AUTOSAR XML (schema 00049)
package /RB/PT/PCT_DcmSample_Requester/SwComponentTypes
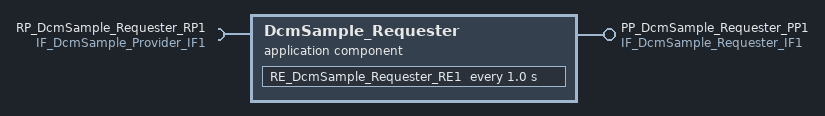
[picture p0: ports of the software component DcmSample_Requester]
  application sw component type DcmSample_Requester
    provide port PP_DcmSample_Requester_PP1: provided-interface=IF_DcmSample_Requester_IF1
    require port RP_DcmSample_Requester_RP1: required-interface=IF_DcmSample_Provider_IF1
    behavior IB_DcmSample_Requester_IB1: data-type-mapping=DTMS_DcmSample_Requester
      timing event TE_DcmSample_Requester_TE1: start-on-event=RE_DcmSample_Requester_RE1, period=1.0
      runnable RE_DcmSample_Requester_RE1: symbol=DcmSample_Requester_1000ms
        data-receive-point-by-values:
          access DRP_DcmSample_Requester_DRP1: accessed-variable=RP_DcmSample_Requester_RP1.VDP_DcmSample_Provider_Var1
        data-send-points:
          access DSP_DcmSample_Requester_DSP1: accessed-variable=PP_DcmSample_Requester_PP1.VDP_DcmSample_Requester_Var1
package /RB/PT/PCT_DcmSample_Requester/PortInterfaces
  sender receiver interface IF_DcmSample_Requester_IF1
    data VDP_DcmSample_Requester_Var1: type=ADT_DcmSample_Requester_uint8
  sender receiver interface IF_DcmSample_Provider_IF1
    data VDP_DcmSample_Provider_Var1: type=ADT_DcmSample_Provider_uint8
package /RB/PT/PCT_DcmSample_Requester/ApplicationDataTypes
  app type ADT_DcmSample_Requester_uint8: category=VALUE, sw-calibration-access=READ-ONLY
package /RB/PT/PCT_DcmSample_Requester/ImplementationDataTypes
  impl type IDT_DcmSample_Requester_uint8: implementation-data-type=uint8
package /RB/PT/PCT_DcmSample_Requester/DataTypeMappingSets
  data type mapping set DTMS_DcmSample_Requester
    data-type-maps:
      application-data-type=ADT_DcmSample_Requester_uint8, implementation-data-type=IDT_DcmSample_Requester_uint8
      application-data-type=ADT_DcmSample_Provider_uint8, implementation-data-type=IDT_DcmSample_Provider_uint8
